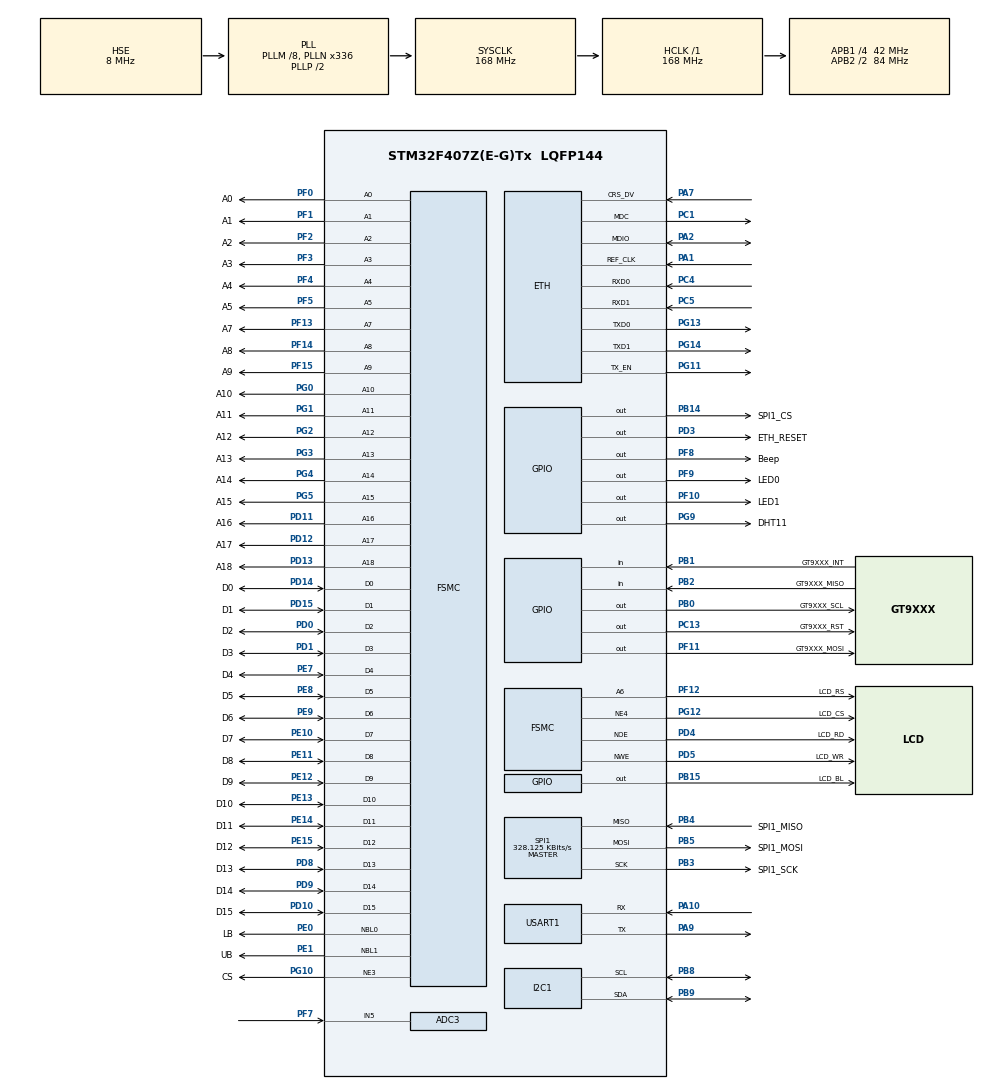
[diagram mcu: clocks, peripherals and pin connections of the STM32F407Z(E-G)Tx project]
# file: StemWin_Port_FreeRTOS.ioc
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ADC3.Channel-0\#ChannelRegularConversion=ADC_CHANNEL_5
ADC3.NbrOfConversionFlag=1
ADC3.Rank-0\#ChannelRegularConversion=1
ADC3.SamplingTime-0\#ChannelRegularConversion=ADC_SAMPLETIME_3CYCLES
ETH.MediaInterface=ETH_MEDIA_INTERFACE_RMII
ETH.PHY_DUPLEX_STATUS=0x2000
ETH.PHY_Name_RMII=userPHY
ETH.PHY_SPEED_STATUS=0x4010
ETH.PHY_SR=0x11
ETH.PhyAddress=0
FREERTOS.HEAP_NUMBER=5
FREERTOS.MEMORY_ALLOCATION=0
FREERTOS.Tasks01=WebServer,2,256,WebServer_Task,Default,NULL,Dynamic,NULL,NULL;Touch,1,256,Touch_Task,Default,NULL,Dynamic,NULL,NULL;IOT,0,256,IOT_Task,Default,NULL,Dynamic,NULL,NULL;GUI,-1,2048,GUI_Task,Default,NULL,Dynamic,NULL,NULL
FREERTOS.configTOTAL_HEAP_SIZE=40960
FSMC.AddressSetupTime1=2
FSMC.BusTurnAroundDuration1=0
FSMC.DataSetupTime1=8
FSMC.DataSetupTime2=60
FSMC.ExtendedAddressSetupTime2=9
FSMC.ExtendedDataSetupTime2=9
FSMC.ExtendedMode2=FSMC_EXTENDED_MODE_ENABLE
FSMC.WriteOperation1=FSMC_WRITE_OPERATION_ENABLE
LWIP.GATEWAY_ADDRESS=010.010.001.001
LWIP.IP_ADDRESS=010.010.001.022
LWIP.LWIP_DHCP=0
LWIP.LWIP_NETIF_LINK_CALLBACK=1
LWIP.MEMP_MEM_MALLOC=1
LWIP.MEM_SIZE=16384
LWIP.NETMASK_ADDRESS=255.255.255.000
LWIP.Version=v2.0.3_Cube
Mcu.Family=STM32F4
Mcu.Name=STM32F407Z(E-G)Tx
Mcu.Package=LQFP144
NVIC.ETH_IRQn=true\:5\:0\:false\:false\:true\:true\:true\:true
NVIC.PriorityGroup=NVIC_PRIORITYGROUP_4
NVIC.TIM1_UP_TIM10_IRQn=true\:0\:0\:false\:false\:true\:false\:false\:true
NVIC.TimeBase=TIM1_UP_TIM10_IRQn
NVIC.TimeBaseIP=TIM1
PA1.Mode=RMII
PA1.Signal=ETH_REF_CLK
PA10.Mode=Asynchronous
PA10.Signal=USART1_RX
PA13.Mode=Serial_Wire
PA13.Signal=SYS_JTMS-SWDIO
PA14.Mode=Serial_Wire
PA14.Signal=SYS_JTCK-SWCLK
PA2.Mode=RMII
PA2.Signal=ETH_MDIO
PA7.Mode=RMII
PA7.Signal=ETH_CRS_DV
PA9.Mode=Asynchronous
PA9.Signal=USART1_TX
PB0.GPIO_Label=GT9XXX_SCL
PB0.GPIO_PuPd=GPIO_PULLUP
PB0.GPIO_Speed=GPIO_SPEED_FREQ_VERY_HIGH
PB0.Signal=GPIO_Output
PB1.GPIO_Label=GT9XXX_INT
PB1.Signal=GPIO_Input
PB14.GPIO_Label=SPI1_CS
PB14.GPIO_PuPd=GPIO_PULLUP
PB14.GPIO_Speed=GPIO_SPEED_FREQ_HIGH
PB14.PinState=GPIO_PIN_SET
PB14.Signal=GPIO_Output
PB15.GPIO_Label=LCD_BL
PB15.GPIO_PuPd=GPIO_PULLDOWN
PB15.GPIO_Speed=GPIO_SPEED_FREQ_HIGH
PB15.PinState=GPIO_PIN_SET
PB15.Signal=GPIO_Output
PB2.GPIO_Label=GT9XXX_MISO
PB2.GPIO_PuPd=GPIO_PULLUP
PB2.Signal=GPIO_Input
PB3.GPIO_Label=SPI1_SCK
PB3.GPIO_PuPd=GPIO_PULLUP
PB3.Mode=Full_Duplex_Master
PB3.Signal=SPI1_SCK
PB4.GPIO_Label=SPI1_MISO
PB4.GPIO_PuPd=GPIO_PULLUP
PB4.Mode=Full_Duplex_Master
PB4.Signal=SPI1_MISO
PB5.GPIO_Label=SPI1_MOSI
PB5.GPIO_PuPd=GPIO_PULLUP
PB5.Mode=Full_Duplex_Master
PB5.Signal=SPI1_MOSI
PB8.Mode=I2C
PB8.Signal=I2C1_SCL
PB9.Mode=I2C
PB9.Signal=I2C1_SDA
PC1.Mode=RMII
PC1.Signal=ETH_MDC
PC13-ANTI_TAMP.GPIO_Label=GT9XXX_RST
PC13-ANTI_TAMP.GPIO_PuPd=GPIO_PULLUP
PC13-ANTI_TAMP.Signal=GPIO_Output
PC4.Mode=RMII
PC4.Signal=ETH_RXD0
PC5.Mode=RMII
PC5.Signal=ETH_RXD1
PD0.GPIO_Label=D2
PD0.GPIO_PuPd=GPIO_PULLUP
PD0.Signal=FSMC_D2_DA2
PD1.GPIO_Label=D3
PD1.GPIO_PuPd=GPIO_PULLUP
PD1.Signal=FSMC_D3_DA3
PD10.GPIO_Label=D15
PD10.GPIO_PuPd=GPIO_PULLUP
PD10.Signal=FSMC_D15_DA15
PD11.GPIO_Label=A16
PD11.GPIO_PuPd=GPIO_PULLUP
PD11.Signal=FSMC_A16_CLE
PD12.GPIO_Label=A17
PD12.GPIO_PuPd=GPIO_PULLUP
PD12.Signal=FSMC_A17_ALE
PD13.GPIO_Label=A18
PD13.GPIO_PuPd=GPIO_PULLUP
PD13.Signal=FSMC_A18
PD14.GPIO_Label=D0
PD14.GPIO_PuPd=GPIO_PULLUP
PD14.Signal=FSMC_D0_DA0
PD15.GPIO_Label=D1
PD15.GPIO_PuPd=GPIO_PULLUP
PD15.Signal=FSMC_D1_DA1
PD3.GPIO_Label=ETH_RESET
PD3.GPIO_Speed=GPIO_SPEED_FREQ_VERY_HIGH
PD3.PinState=GPIO_PIN_SET
PD3.Signal=GPIO_Output
PD4.GPIO_Label=LCD_RD
PD4.GPIO_PuPd=GPIO_PULLUP
PD4.Signal=FSMC_NOE
PD5.GPIO_Label=LCD_WR
PD5.GPIO_PuPd=GPIO_PULLUP
PD5.Signal=FSMC_NWE
PD8.GPIO_Label=D13
PD8.GPIO_PuPd=GPIO_PULLUP
PD8.Signal=FSMC_D13_DA13
PD9.GPIO_Label=D14
PD9.GPIO_PuPd=GPIO_PULLUP
PD9.Signal=FSMC_D14_DA14
PE0.GPIO_Label=LB
PE0.GPIO_PuPd=GPIO_PULLUP
PE0.Signal=FSMC_NBL0
PE1.GPIO_Label=UB
PE1.GPIO_PuPd=GPIO_PULLUP
PE1.Signal=FSMC_NBL1
PE10.GPIO_Label=D7
PE10.GPIO_PuPd=GPIO_PULLUP
PE10.Signal=FSMC_D7_DA7
PE11.GPIO_Label=D8
PE11.GPIO_PuPd=GPIO_PULLUP
PE11.Signal=FSMC_D8_DA8
PE12.GPIO_Label=D9
PE12.GPIO_PuPd=GPIO_PULLUP
PE12.Signal=FSMC_D9_DA9
PE13.GPIO_Label=D10
PE13.GPIO_PuPd=GPIO_PULLUP
PE13.Signal=FSMC_D10_DA10
PE14.GPIO_Label=D11
PE14.GPIO_PuPd=GPIO_PULLUP
PE14.Signal=FSMC_D11_DA11
PE15.GPIO_Label=D12
PE15.GPIO_PuPd=GPIO_PULLUP
PE15.Signal=FSMC_D12_DA12
PE7.GPIO_Label=D4
PE7.GPIO_PuPd=GPIO_PULLUP
PE7.Signal=FSMC_D4_DA4
PE8.GPIO_Label=D5
PE8.GPIO_PuPd=GPIO_PULLUP
PE8.Signal=FSMC_D5_DA5
PE9.GPIO_Label=D6
PE9.GPIO_PuPd=GPIO_PULLUP
PE9.Signal=FSMC_D6_DA6
PF0.GPIO_Label=A0
PF0.GPIO_PuPd=GPIO_PULLUP
PF0.Signal=FSMC_A0
PF1.GPIO_Label=A1
PF1.GPIO_PuPd=GPIO_PULLUP
PF1.Signal=FSMC_A1
PF10.GPIO_Label=LED1
PF10.GPIO_ModeDefaultOutputPP=GPIO_MODE_OUTPUT_PP
PF10.GPIO_PuPd=GPIO_PULLUP
PF10.GPIO_Speed=GPIO_SPEED_FREQ_HIGH
PF10.PinState=GPIO_PIN_SET
PF10.Signal=GPIO_Output
PF11.GPIO_Label=GT9XXX_MOSI
PF11.GPIO_ModeDefaultOutputPP=GPIO_MODE_OUTPUT_OD
PF11.GPIO_PuPd=GPIO_PULLUP
PF11.GPIO_Speed=GPIO_SPEED_FREQ_VERY_HIGH
PF11.Signal=GPIO_Output
PF12.GPIO_Label=LCD_RS
PF12.GPIO_PuPd=GPIO_PULLUP
PF12.Signal=FSMC_A6
PF13.GPIO_Label=A7
PF13.GPIO_PuPd=GPIO_PULLUP
PF13.Signal=FSMC_A7
PF14.GPIO_Label=A8
PF14.GPIO_PuPd=GPIO_PULLUP
PF14.Signal=FSMC_A8
PF15.GPIO_Label=A9
PF15.GPIO_PuPd=GPIO_PULLUP
PF15.Signal=FSMC_A9
PF2.GPIO_Label=A2
PF2.GPIO_PuPd=GPIO_PULLUP
PF2.Signal=FSMC_A2
PF3.GPIO_Label=A3
PF3.GPIO_PuPd=GPIO_PULLUP
PF3.Signal=FSMC_A3
PF4.GPIO_Label=A4
PF4.GPIO_PuPd=GPIO_PULLUP
PF4.Signal=FSMC_A4
PF5.GPIO_Label=A5
PF5.GPIO_PuPd=GPIO_PULLUP
PF5.Signal=FSMC_A5
PF7.Mode=IN5
PF7.Signal=ADC3_IN5
PF8.GPIO_Label=Beep
PF8.GPIO_PuPd=GPIO_PULLDOWN
PF8.GPIO_Speed=GPIO_SPEED_FREQ_VERY_HIGH
PF8.PinState=GPIO_PIN_RESET
PF8.Signal=GPIO_Output
PF9.GPIO_Label=LED0
PF9.GPIO_PuPd=GPIO_PULLUP
PF9.GPIO_Speed=GPIO_SPEED_FREQ_HIGH
PF9.PinState=GPIO_PIN_SET
PF9.Signal=GPIO_Output
PG0.GPIO_Label=A10
PG0.GPIO_PuPd=GPIO_PULLUP
PG0.Signal=FSMC_A10
PG1.GPIO_Label=A11
PG1.GPIO_PuPd=GPIO_PULLUP
PG1.Signal=FSMC_A11
PG10.GPIO_Label=CS
PG10.GPIO_PuPd=GPIO_PULLUP
PG10.Mode=NorPsramChipSelect3_1
PG10.Signal=FSMC_NE3
PG11.Mode=RMII
PG11.Signal=ETH_TX_EN
PG12.GPIO_Label=LCD_CS
PG12.GPIO_PuPd=GPIO_PULLUP
PG12.Mode=NorPsramChipSelect4_2
PG12.Signal=FSMC_NE4
PG13.Mode=RMII
PG13.Signal=ETH_TXD0
PG14.Mode=RMII
PG14.Signal=ETH_TXD1
PG2.GPIO_Label=A12
PG2.GPIO_PuPd=GPIO_PULLUP
PG2.Signal=FSMC_A12
PG3.GPIO_Label=A13
PG3.GPIO_PuPd=GPIO_PULLUP
PG3.Signal=FSMC_A13
PG4.GPIO_Label=A14
PG4.GPIO_PuPd=GPIO_PULLUP
PG4.Signal=FSMC_A14
PG5.GPIO_Label=A15
PG5.GPIO_PuPd=GPIO_PULLUP
PG5.Signal=FSMC_A15
PG9.GPIO_Label=DHT11
PG9.GPIO_ModeDefaultOutputPP=GPIO_MODE_OUTPUT_OD
PG9.GPIO_PuPd=GPIO_PULLUP
PG9.GPIO_Speed=GPIO_SPEED_FREQ_VERY_HIGH
PG9.PinState=GPIO_PIN_SET
PG9.Signal=GPIO_Output
PH0-OSC_IN.Mode=HSE-External-Oscillator
PH0-OSC_IN.Signal=RCC_OSC_IN
PH1-OSC_OUT.Mode=HSE-External-Oscillator
PH1-OSC_OUT.Signal=RCC_OSC_OUT
ProjectManager.HeapSize=0x400
ProjectManager.StackSize=0x200
ProjectManager.TargetToolchain=MDK-ARM V5
RCC.48MHZClocksFreq_Value=84000000
RCC.AHBFreq_Value=168000000
RCC.APB1CLKDivider=RCC_HCLK_DIV4
RCC.APB1Freq_Value=42000000
RCC.APB1TimFreq_Value=84000000
RCC.APB2CLKDivider=RCC_HCLK_DIV2
RCC.APB2Freq_Value=84000000
RCC.APB2TimFreq_Value=168000000
RCC.CortexFreq_Value=168000000
RCC.HCLKFreq_Value=168000000
RCC.HSE_VALUE=8000000
RCC.HSI_VALUE=16000000
RCC.LSE_VALUE=32768
RCC.PLLM=8
RCC.PLLN=336
RCC.PLLSourceVirtual=RCC_PLLSOURCE_HSE
RCC.SYSCLKFreq_VALUE=168000000
RCC.SYSCLKSource=RCC_SYSCLKSOURCE_PLLCLK
RCC.VCOOutputFreq_Value=336000000
SH.FSMC_A0.0=FSMC_A0,19b-a1
SH.FSMC_A1.0=FSMC_A1,19b-a1
SH.FSMC_A10.0=FSMC_A10,19b-a1
SH.FSMC_A11.0=FSMC_A11,19b-a1
SH.FSMC_A12.0=FSMC_A12,19b-a1
SH.FSMC_A13.0=FSMC_A13,19b-a1
SH.FSMC_A14.0=FSMC_A14,19b-a1
SH.FSMC_A15.0=FSMC_A15,19b-a1
SH.FSMC_A16_CLE.0=FSMC_A16,19b-a1
SH.FSMC_A17_ALE.0=FSMC_A17,19b-a1
SH.FSMC_A18.0=FSMC_A18,19b-a1
SH.FSMC_A2.0=FSMC_A2,19b-a1
SH.FSMC_A3.0=FSMC_A3,19b-a1
SH.FSMC_A4.0=FSMC_A4,19b-a1
SH.FSMC_A5.0=FSMC_A5,19b-a1
SH.FSMC_A6.0=FSMC_A6,A6_2
SH.FSMC_A6.1=FSMC_A6,19b-a1
SH.FSMC_A7.0=FSMC_A7,19b-a1
SH.FSMC_A8.0=FSMC_A8,19b-a1
SH.FSMC_A9.0=FSMC_A9,19b-a1
SH.FSMC_D0_DA0.0=FSMC_D0,16b-d2
SH.FSMC_D0_DA0.1=FSMC_D0,16b-d1
SH.FSMC_D10_DA10.0=FSMC_D10,16b-d2
SH.FSMC_D10_DA10.1=FSMC_D10,16b-d1
SH.FSMC_D11_DA11.0=FSMC_D11,16b-d2
SH.FSMC_D11_DA11.1=FSMC_D11,16b-d1
SH.FSMC_D12_DA12.0=FSMC_D12,16b-d2
SH.FSMC_D12_DA12.1=FSMC_D12,16b-d1
SH.FSMC_D13_DA13.0=FSMC_D13,16b-d2
SH.FSMC_D13_DA13.1=FSMC_D13,16b-d1
SH.FSMC_D14_DA14.0=FSMC_D14,16b-d2
SH.FSMC_D14_DA14.1=FSMC_D14,16b-d1
SH.FSMC_D15_DA15.0=FSMC_D15,16b-d2
SH.FSMC_D15_DA15.1=FSMC_D15,16b-d1
SH.FSMC_D1_DA1.0=FSMC_D1,16b-d2
SH.FSMC_D1_DA1.1=FSMC_D1,16b-d1
SH.FSMC_D2_DA2.0=FSMC_D2,16b-d2
SH.FSMC_D2_DA2.1=FSMC_D2,16b-d1
SH.FSMC_D3_DA3.0=FSMC_D3,16b-d2
SH.FSMC_D3_DA3.1=FSMC_D3,16b-d1
SH.FSMC_D4_DA4.0=FSMC_D4,16b-d2
SH.FSMC_D4_DA4.1=FSMC_D4,16b-d1
SH.FSMC_D5_DA5.0=FSMC_D5,16b-d2
SH.FSMC_D5_DA5.1=FSMC_D5,16b-d1
SH.FSMC_D6_DA6.0=FSMC_D6,16b-d2
SH.FSMC_D6_DA6.1=FSMC_D6,16b-d1
SH.FSMC_D7_DA7.0=FSMC_D7,16b-d2
SH.FSMC_D7_DA7.1=FSMC_D7,16b-d1
SH.FSMC_D8_DA8.0=FSMC_D8,16b-d2
SH.FSMC_D8_DA8.1=FSMC_D8,16b-d1
SH.FSMC_D9_DA9.0=FSMC_D9,16b-d2
SH.FSMC_D9_DA9.1=FSMC_D9,16b-d1
SH.FSMC_NBL0.0=FSMC_NBL0,2ByteEnable1
SH.FSMC_NBL1.0=FSMC_NBL1,2ByteEnable1
SH.FSMC_NOE.0=FSMC_NOE,Lcd2
SH.FSMC_NOE.1=FSMC_NOE,Sram1
SH.FSMC_NWE.0=FSMC_NWE,Lcd2
SH.FSMC_NWE.1=FSMC_NWE,Sram1
SPI1.BaudRatePrescaler=SPI_BAUDRATEPRESCALER_256
SPI1.CLKPhase=SPI_PHASE_2EDGE
SPI1.CLKPolarity=SPI_POLARITY_HIGH
SPI1.CalculateBaudRate=328.125 KBits/s
SPI1.Direction=SPI_DIRECTION_2LINES
SPI1.Mode=SPI_MODE_MASTER
SPI1.VirtualType=VM_MASTER
USART1.VirtualMode=VM_ASYNC
VP_CRC_VS_CRC.Mode=CRC_Activate
VP_FREERTOS_VS_CMSIS_V1.Mode=CMSIS_V1
VP_LWIP_VS_Enabled.Mode=Enabled
VP_SYS_VS_tim1.Mode=TIM1
board=custom

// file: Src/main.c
/* USER CODE BEGIN Header */
/**
  ******************************************************************************
  * @file           : main.c
  * @brief          : Main program body
  ******************************************************************************
  * @attention
  *
  * <h2><center>&copy; Copyright (c) 2024 STMicroelectronics.
  * All rights reserved.</center></h2>
  *
  * This software component is licensed by ST under BSD 3-Clause license,
  * the "License"; You may not use this file except in compliance with the
  * License. You may obtain a copy of the License at:
  *                        opensource.org/licenses/BSD-3-Clause
  *
  ******************************************************************************
  */
/* USER CODE END Header */

#include "main.h"
#include "cmsis_os.h"
#include "adc.h"
#include "crc.h"
#include "i2c.h"
#include "lwip.h"
#include "spi.h"
#include "usart.h"
#include "gpio.h"
#include "fsmc.h"

/* USER CODE BEGIN Includes */
#include "sram.h"  //sram_init
#include "mymalloc.h"  //my_mem_init

#include "FreeRTOS.h"
#include "task.h"

#include "delay.h"
#include "lcd.h"

#include "lwipopts.h"  //lwipopts.h

#include "GUI.h"  //GUI_PID_STATE
/* USER CODE END Includes */

/* USER CODE BEGIN PV */
// 定义堆区域数组
HeapRegion_t xHeapRegions[] = {
    { ( uint8_t * ) 0x68000000, 0xa000 },  // 定义从0x68000000开始的40K字节内存块
    { NULL, 0 }                            // 终止数组
};

void configureHeapRegions(void)
{
    vPortDefineHeapRegions(xHeapRegions);  // 定义堆区域
}

uint8_t paddr[20] = {0};                  /* 存放内存EXSRAM使用率 */
uint16_t memused = 0;                     /* 内存使用百分比 */

uint8_t lcd_id[12];
uint16_t colors[12] = {WHITE, BLACK, BLUE, RED, MAGENTA, GREEN, CYAN, YELLOW, BRRED, GRAY, LGRAY, BROWN};uint8_t color_index = 0;
uint8_t cur_brightness;
uint8_t* str[23];
/* USER CODE END PV */

void SystemClock_Config(void);
void MX_FREERTOS_Init(void);

int main(void)
{

  /* MCU Configuration--------------------------------------------------------*/

  /* Reset of all peripherals, Initializes the Flash interface and the Systick. */
  HAL_Init();

  /* Configure the system clock */
  SystemClock_Config();

  /* Initialize all configured peripherals */
  MX_GPIO_Init();
  MX_USART1_UART_Init();
  MX_FSMC_Init();
  MX_I2C1_Init();
  MX_CRC_Init();
  MX_SPI1_Init();
  MX_ADC3_Init();
  /* USER CODE BEGIN 2 */
		// 调用配置堆区域的函数
	configureHeapRegions();  //FreeRTOS定义heap5的堆区地址范围

	sram_init();                        /* 外扩SRAM初始化 */

	//my_mem_init(SRAMIN);                /* 初始化内部SRAM内存池 */
	my_mem_init(SRAMEX);                /* 初始化外部SRAM内存池 */
	my_mem_init(SRAMCCM);               /* 初始化内部CCM内存池 */

	//因为将外扩SRAM的头部40KB给FreeRTOS使用，所以要将这部分在内存管理表中对应的表项赋值为非零，表示已经被占用了，防止影响FreeRTOS的堆区
	my_mem_occupy(SRAMEX, 40*1024);

	memused = my_mem_perused(SRAMEX);
	sprintf((char *)paddr, "%d.%01d%%", memused / 10, memused % 10);
	printf("SRAMEX   USED: %s\n", (char *)paddr);

	//因为在外扩SRAM紧跟着FreeRTOS的空间后面给LWIP分配MEM_SIZE大小的空间，所以要将这部分在内存管理表中对应的表项赋值为非零
	my_mem_occupy_from(SRAMEX, 40*1024, MEM_SIZE);
	memused = my_mem_perused(SRAMEX);
	sprintf((char *)paddr, "%d.%01d%%", memused / 10, memused % 10);
	printf("SRAMEX   USED: %s\n", (char *)paddr);
  /* USER CODE END 2 */

  /* Call init function for freertos objects (in freertos.c) */
  MX_FREERTOS_Init();

  /* Start scheduler */
  osKernelStart();

  /* We should never get here as control is now taken by the scheduler */

  /* Infinite loop */
  while (1)
  {

  }
}

void SystemClock_Config(void)
{
  RCC_OscInitTypeDef RCC_OscInitStruct = {0};
  RCC_ClkInitTypeDef RCC_ClkInitStruct = {0};

  /** Configure the main internal regulator output voltage
  */
  __HAL_RCC_PWR_CLK_ENABLE();
  __HAL_PWR_VOLTAGESCALING_CONFIG(PWR_REGULATOR_VOLTAGE_SCALE1);
  /** Initializes the CPU, AHB and APB busses clocks
  */
  RCC_OscInitStruct.OscillatorType = RCC_OSCILLATORTYPE_HSE;
  RCC_OscInitStruct.HSEState = RCC_HSE_ON;
  RCC_OscInitStruct.PLL.PLLState = RCC_PLL_ON;
  RCC_OscInitStruct.PLL.PLLSource = RCC_PLLSOURCE_HSE;
  RCC_OscInitStruct.PLL.PLLM = 8;
  RCC_OscInitStruct.PLL.PLLN = 336;
  RCC_OscInitStruct.PLL.PLLP = RCC_PLLP_DIV2;
  RCC_OscInitStruct.PLL.PLLQ = 4;
  if (HAL_RCC_OscConfig(&RCC_OscInitStruct) != HAL_OK)
  {
    Error_Handler();
  }
  /** Initializes the CPU, AHB and APB busses clocks
  */
  RCC_ClkInitStruct.ClockType = RCC_CLOCKTYPE_HCLK|RCC_CLOCKTYPE_SYSCLK
                              |RCC_CLOCKTYPE_PCLK1|RCC_CLOCKTYPE_PCLK2;
  RCC_ClkInitStruct.SYSCLKSource = RCC_SYSCLKSOURCE_PLLCLK;
  RCC_ClkInitStruct.AHBCLKDivider = RCC_SYSCLK_DIV1;
  RCC_ClkInitStruct.APB1CLKDivider = RCC_HCLK_DIV4;
  RCC_ClkInitStruct.APB2CLKDivider = RCC_HCLK_DIV2;

  if (HAL_RCC_ClockConfig(&RCC_ClkInitStruct, FLASH_LATENCY_5) != HAL_OK)
  {
    Error_Handler();
  }
}

/* USER CODE BEGIN 4 */
void emwin_test_touch(void){
	GUI_PID_STATE State;
	GUI_Init();
	GUI_SetBkColor(GUI_BLUE);
	GUI_SetFont(&GUI_Font20_ASCII);
	GUI_SetColor(GUI_YELLOW);
	GUI_Clear();
	while(1){
		//执行触摸笔检测
		GUI_TOUCH_Exec();
		//获取触摸笔状态值
		GUI_TOUCH_GetState(&State);
		//是否按下
		if(State.Pressed){
			//打印触摸笔坐标信息
			GUI_DispStringAt("X:", 0, 0);
			GUI_DispDecAt(State.x, 32, 0, 4);
			GUI_DispStringAt("Y:", 0, 24);
			GUI_DispDecAt(State.y, 32, 24, 4);

			GUI_DispStringAt("EXIT", lcddev.width - 40, 0);
		}

		delay_ms(10);
		if (State.x > lcddev.width - 40 && State.y < 20) //按EXIT
		{
				GUI_SetBkColor(GUI_WHITE);
				GUI_Clear();
				return;  //退出测试死循环
		}
	}
}
/* USER CODE END 4 */

void HAL_TIM_PeriodElapsedCallback(TIM_HandleTypeDef *htim)
{
  if (htim->Instance == TIM1) {
    HAL_IncTick();
  }
}

void Error_Handler(void)
{
}

/************************ (C) COPYRIGHT STMicroelectronics *****END OF FILE****/

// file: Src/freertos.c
/* USER CODE BEGIN Header */
/**
  ******************************************************************************
  * File Name          : freertos.c
  * Description        : Code for freertos applications
  ******************************************************************************
  * @attention
  *
  * <h2><center>&copy; Copyright (c) 2024 STMicroelectronics.
  * All rights reserved.</center></h2>
  *
  * This software component is licensed by ST under Ultimate Liberty license
  * SLA0044, the "License"; You may not use this file except in compliance with
  * the License. You may obtain a copy of the License at:
  *                             www.st.com/SLA0044
  *
  ******************************************************************************
  */
/* USER CODE END Header */

#include "FreeRTOS.h"
#include "task.h"
#include "main.h"
#include "cmsis_os.h"

/* USER CODE BEGIN Includes */
#include "delay.h"
#include "lcd.h"
#include "stdio.h"  //sprintf

#include "touch.h"  //tp_dev
#include "norflash.h"  //norflash_init

#include "dht11.h"  //dht11_init��dht11_read_data

#include "lsens.h"  //lsens_init

#include "GUI.h"  //GUI_TOUCH_Exec
/* USER CODE END Includes */

/* USER CODE BEGIN Variables */
//lcd
extern uint8_t lcd_id[12]; //main.c
extern uint16_t colors[];  //main.c
extern uint8_t color_index;  //main.c

uint16_t id;  //norflash id

uint8_t t = 0;
uint16_t temperature;
uint16_t humidity;

uint16_t adcx;
/* USER CODE END Variables */
osThreadId WebServerHandle;
osThreadId TouchHandle;
osThreadId IOTHandle;
osThreadId GUIHandle;

/* USER CODE BEGIN FunctionPrototypes */
extern void MainTask(void);
/* USER CODE END FunctionPrototypes */

void WebServer_Task(void const * argument);
void Touch_Task(void const * argument);
void IOT_Task(void const * argument);
void GUI_Task(void const * argument);

extern void MX_LWIP_Init(void);
void MX_FREERTOS_Init(void); /* (MISRA C 2004 rule 8.1) */

void MX_FREERTOS_Init(void) {

  /* Create the thread(s) */
  /* definition and creation of WebServer */
  osThreadDef(WebServer, WebServer_Task, osPriorityHigh, 0, 256);
  WebServerHandle = osThreadCreate(osThread(WebServer), NULL);

  /* definition and creation of Touch */
  osThreadDef(Touch, Touch_Task, osPriorityAboveNormal, 0, 256);
  TouchHandle = osThreadCreate(osThread(Touch), NULL);

  /* definition and creation of IOT */
  osThreadDef(IOT, IOT_Task, osPriorityNormal, 0, 256);
  IOTHandle = osThreadCreate(osThread(IOT), NULL);

  /* definition and creation of GUI */
  osThreadDef(GUI, GUI_Task, osPriorityBelowNormal, 0, 2048);
  GUIHandle = osThreadCreate(osThread(GUI), NULL);

}

void WebServer_Task(void const * argument)
{

  /* init code for LWIP */
  MX_LWIP_Init();

  /* USER CODE BEGIN WebServer_Task */
	taskENTER_CRITICAL();           /* 进入临界�? */
	//SPI Flash
	norflash_init();  //初始化norflash
	id = norflash_read_id();
	printf("norflash id is %d\n", id);

	taskEXIT_CRITICAL();            /* �?出临界区 */
  /* Infinite loop */
  for(;;)
  {

		osDelay(10);
  }
  /* USER CODE END WebServer_Task */
}

void Touch_Task(void const * argument)
{
  /* USER CODE BEGIN Touch_Task */
	taskENTER_CRITICAL();           /* 进入临界�? */
	delay_init(168);                        /* 延时初始�? */
	lcd_init();                             /* 初始化LCD */
  g_point_color = RED;
  sprintf((char *)lcd_id, "LCD ID:%04X", lcddev.id);  /* 将LCD ID打印到lcd_id数组 */
	HAL_GPIO_WritePin(LED1_GPIO_Port, LED1_Pin, GPIO_PIN_RESET);  //LED1�?
	lcd_set_backlight_by_pwm(0xFF); // 设置占空比为255，开启背光最�?
	lcd_clear(colors[color_index]);  //清屏

	//screen touch init
	uint8_t res = tp_dev.init();                      // 触摸屏初始化
	if(!res){
		printf("LCD Touch init Successful!\n");
	}
	while (dht11_init())    /* DHT11��ʼ�� */
	{
			printf("DHT11 Error !\n");
			delay_ms(200);
	}

	lsens_init();                           /* ��ʼ������������ */

	//emwin_test_touch();  //emWin坐标获取
	taskEXIT_CRITICAL();            /* �?出临界区 */
  /* Infinite loop */
  for(;;)
  {
		if (t % 5 == 0) /* ÿ100ms��ȡһ�� */ {
				dht11_read_data(&temperature, &humidity); /* ��ȡ��ʪ��ֵ */

				printf("temperature: %d.%d\n", temperature>>8, (temperature & 0xFF));/* ��ʾ�¶� */
				printf("humidity: %d.%d", humidity>>8, (humidity & 0xFF)); /* ��ʾʪ�� */
		}
		if(t % 10 == 0) /* ÿ200ms��ȡһ�� */{
				adcx = lsens_get_val();                                 /* ��ȡADCֵ */
				printf("bright:%d\n", adcx);
		}
		t++;
		//触摸屏需要轮询检测，否则emWin没有办法触发事件
		GUI_TOUCH_Exec();
    osDelay(20);
  }
  /* USER CODE END Touch_Task */
}

void IOT_Task(void const * argument)
{
  for(;;)
  {
    osDelay(1);
  }
}

void GUI_Task(void const * argument)
{
  /* USER CODE BEGIN GUI_Task */
	MainTask();
  /* Infinite loop */
	/*
  for(;;)
  {
    osDelay(1);
  }
	*/
  /* USER CODE END GUI_Task */
}

/************************ (C) COPYRIGHT STMicroelectronics *****END OF FILE****/
